# AT32F423 register map
Vendor: Keil; Series: AT32F423; File version: 1.0
CPU: CM4 r0p1, little endian, no MPU, FPU, 4 interrupt priority bits
Registers are 32-bit, read-write, reset 0x0 unless marked. A register's access mark holds for its fields unless they carry their own. Offsets are from the block's base; [hi:lo] are bit positions; {n}, {i} and the like mark numbered series; 'fields as' and 'values as' point back to an identical list.

## XMC — Flexible static memory controller
Base 0xA0000000
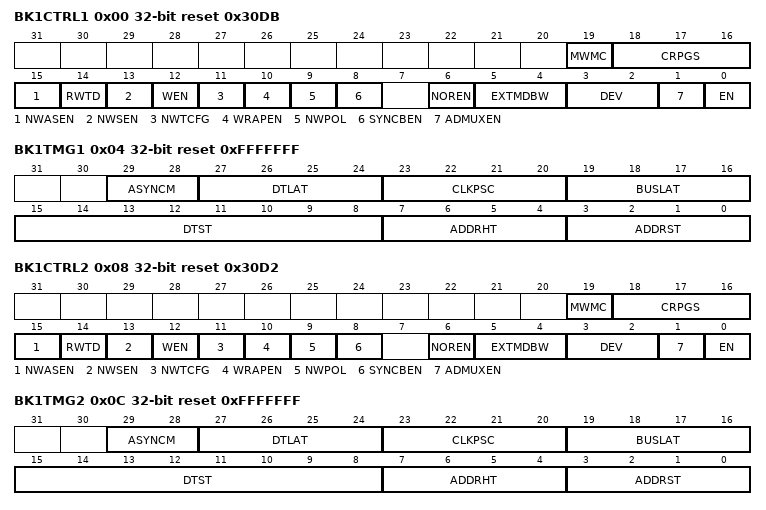
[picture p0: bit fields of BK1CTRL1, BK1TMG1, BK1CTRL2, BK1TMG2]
0x00 BK1CTRL1 reset 0x30DB — SRAM/NOR-Flash chip-select control register 1
  [19] MWMC — Memory write mode control
  [18:16] CRPGS — CRAM page size
  [15] NWASEN — NWAIT in asynchronous transfer enable
  [14] RWTD — Read-write timing different
  [13] NWSEN — NWAIT in synchronous transfer enable
  [12] WEN — Write enable
  [11] NWTCFG — Wait timing configuration
  [10] WRAPEN — Wrapped enable
  [9] NWPOL — NWAIT polarity
  [8] SYNCBEN — Synchronous burst enable
  [6] NOREN — Nor flash access enable
  [5:4] EXTMDBW — External memory data bus width
  [3:2] DEV — Memory device type
  [1] ADMUXEN — Address and data multiplexing enable
  [0] EN — Memory bank enable
0x04 BK1TMG1 reset 0xFFFFFFF — SRAM/NOR-Flash chip-select timing register 1
  [29:28] ASYNCM — Asynchronous mode
  [27:24] DTLAT — Data latency
  [23:20] CLKPSC — Clock prescale
  [19:16] BUSLAT — Bus latency
  [15:8] DTST — Asynchronous data setup time
  [7:4] ADDRHT — Address-hold time
  [3:0] ADDRST — Address setup time
0x08 BK1CTRL2 reset 0x30D2 — SRAM/NOR-Flash chip-select control register 2
  fields as BK1CTRL1
0x0C BK1TMG2 reset 0xFFFFFFF — SRAM/NOR-Flash chip-select timing register 2
  fields as BK1TMG1
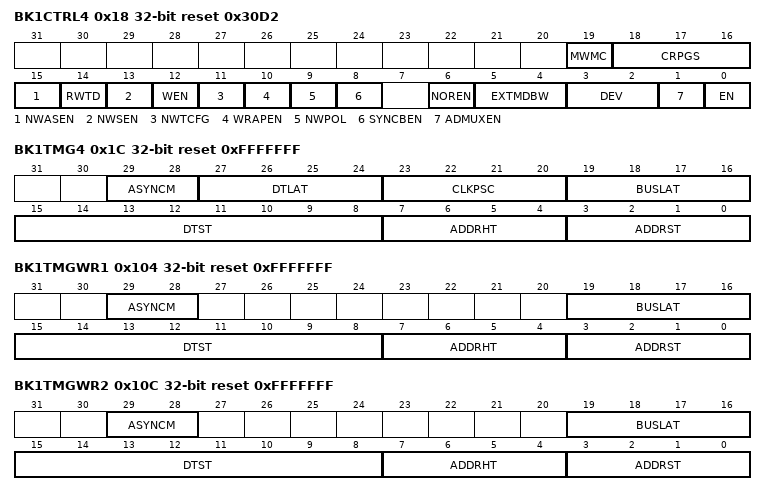
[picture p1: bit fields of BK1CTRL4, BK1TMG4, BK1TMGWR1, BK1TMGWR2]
0x18 BK1CTRL4 reset 0x30D2 — SRAM/NOR-Flash chip-select control register 4
  fields as BK1CTRL1
0x1C BK1TMG4 reset 0xFFFFFFF — SRAM/NOR-Flash chip-select timing register 4
  fields as BK1TMG1
0x104 BK1TMGWR1 reset 0xFFFFFFF — SRAM/NOR-Flash write timing registers 1
  [29:28] ASYNCM — Asynchronous mode
  [19:16] BUSLAT — Bus latency
  [15:8] DTST — Asynchronous data setup time
  [7:4] ADDRHT — Address-hold time
  [3:0] ADDRST — Address setup time
0x10C BK1TMGWR2 reset 0xFFFFFFF — SRAM/NOR-Flash write timing registers 2
  fields as BK1TMGWR1
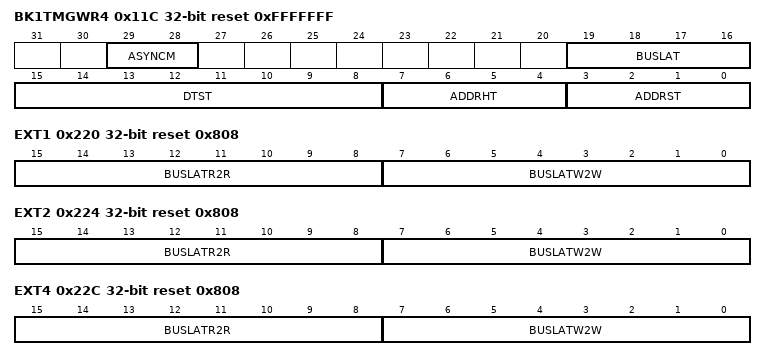
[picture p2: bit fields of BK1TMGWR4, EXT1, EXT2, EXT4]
0x11C BK1TMGWR4 reset 0xFFFFFFF — SRAM/NOR-Flash write timing registers 4
  fields as BK1TMGWR1
0x220 EXT1 reset 0x808 — externl timeing register 1
  [15:8] BUSLATR2R — Bus turnaround phase for consecutive read duration
  [7:0] BUSLATW2W — Bus turnaround phase for consecutive write duration
0x224 EXT2 reset 0x808 — externl timeing register 2
  fields as EXT1
0x22C EXT4 reset 0x808 — externl timeing register 4
  fields as EXT1

## PWC — Power control
Base 0x40007000
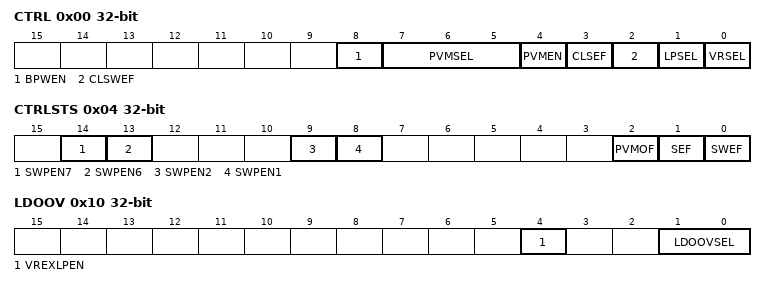
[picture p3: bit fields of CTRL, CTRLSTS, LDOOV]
0x00 CTRL — Power control register (PWC_CTRL)
  [8] BPWEN — Battery powered domain write enable
  [7:5] PVMSEL — Power voltage monitoring boundary select
  [4] PVMEN — Power voltage monitoring enable
  [3] CLSEF — Clear SEF flag
  [2] CLSWEF — Clear SWEF flag
  [1] LPSEL — Low power mode select when Cortex-M4F sleepdeep
  [0] VRSEL — Voltage regulator state select when deepsleep mode
0x04 CTRLSTS — Power control and status register (PWC_CTRLSTS)
  [14] SWPEN7 — Standby wake-up pin 7 enable
  [13] SWPEN6 — Standby wake-up pin 6 enable
  [9] SWPEN2 — Standby wake-up pin 2 enable
  [8] SWPEN1 — Standby wake-up pin 1 enable
  [2] PVMOF ro — Power voltage monitoring output flag
  [1] SEF ro — Standby mode entry flag
  [0] SWEF ro — Standby wake-up event flag
0x10 LDOOV — LDO output voltage register
  [4] VREXLPEN — Voltage regulator extra low power mode enable
  [1:0] LDOOVSEL — LDO output voltage select

## GPIOA — General purpose I/Os
Base 0x40020000
Same registers: GPIOB 0x40020400, GPIOC 0x40020800, GPIOD 0x40020C00, GPIOE 0x40021000, GPIOF 0x40021400
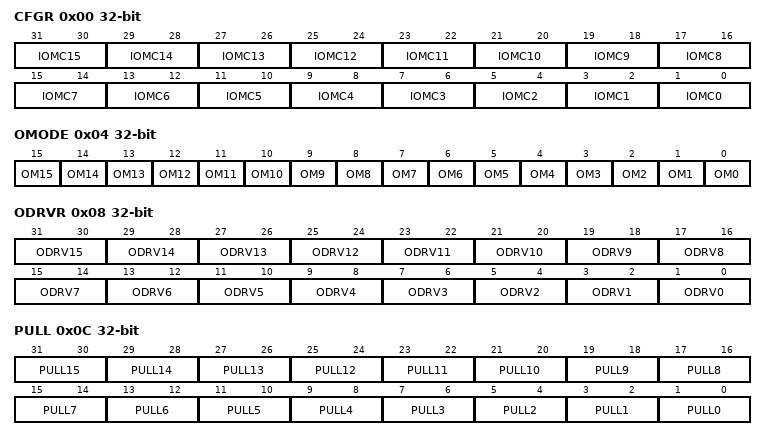
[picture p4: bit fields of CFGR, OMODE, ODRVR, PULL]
0x00 CFGR — GPIO configuration register
  [2n+1:2n] IOMC{n} (n=0..15) — GPIOx pin {n} mode configurate
    0=Input mode; 1=Output (General-purpose output mode); 2=Multiplexed function mode; 3=Analog mode
0x04 OMODE — GPIO output mode register
  [n] OM{n} (n=0..15) — GPIOx pin {n} outpu mode configurate
    0=PushPull; 1=OpenDrain
0x08 ODRVR — GPIO drive capability register
  [2n+1:2n] ODRV{n} (n=0..15) — GPIOx pin {n} output drive capability
    0=Normal sourcing/sinking strength; 1=Large sourcing/sinking strength
0x0C PULL — GPIO pull-up/pull-down register
  [2n+1:2n] PULL{n} (n=0..15) — GPIOx pin {n} pull configuration
    0=No pull-up/pull-down; 1=PullUp; 2=PullDown
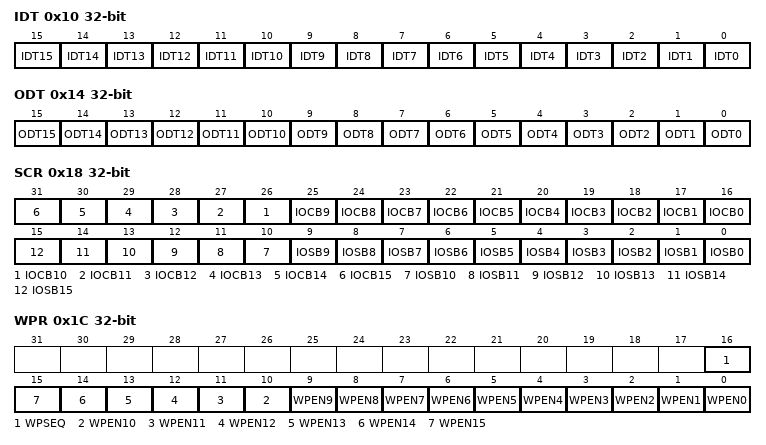
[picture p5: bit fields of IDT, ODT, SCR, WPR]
0x10 IDT ro — GPIO input data register
  [n] IDT{n} (n=0..15) — Port input data
    0=Low (Input is logic low); 1=High (Input is logic high)
0x14 ODT — GPIO output data register
  [n] ODT{n} (n=0..15) — Port output data
    on read: 0=PullDown; 1=PullUp | on write: 0=Low (Set output to logic low); 1=High (Set output to logic high)
0x18 SCR wo — Port bit set/clear register
  [n+16] IOCB{n} (n=0..15) write-1-clears — Clear bit {n}
    1=Clear the corresponding ODT bit
  [n] IOSB{n} (n=0..15) write-1-sets — Set bit {n}
    1=Set (Set the corresponding ODT bit)
0x1C WPR — Port write protect register
  [16] WPSEQ — Write protect sequence
    0=Clear; 1=Set
  [n] WPEN{n} (n=0..15) — Write protect enable {n}
    on read: 0=NotProtected (Port is not write protected); 1=Protected (Port is write protected) | on write: 0=NoProtect (No effect); 1=Protect (Write protect)
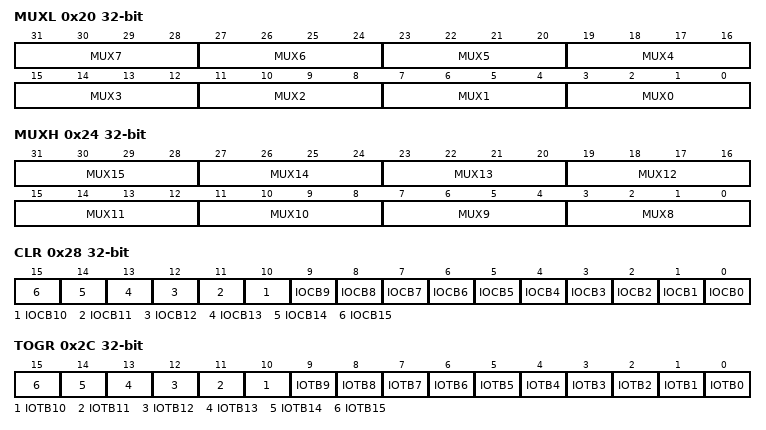
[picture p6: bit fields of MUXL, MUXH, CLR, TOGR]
0x20 MUXL — GPIO muxing function low register
  [4n+3:4n] MUX{n} (n=0..7) — GPIOx pin {n} muxing
0x24 MUXH — GPIO muxing function high register
  [4n-29:4n-32] MUX{n} (n=8..15) — GPIOx pin {n} muxing
0x28 CLR wo — GPIO bit reset register
  [n] IOCB{n} (n=0..15) write-1-clears — Clear bit {n}
    1=Clear the corresponding ODT bit
0x2C TOGR wo — GPIO bit toggle register
  [n] IOTB{n} (n=0..15) — Toggle bit {n}
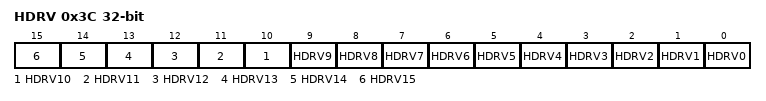
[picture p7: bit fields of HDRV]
0x3C HDRV — Huge current driver
  [n] HDRV{n} (n=0..15) — Port x driver bit y
